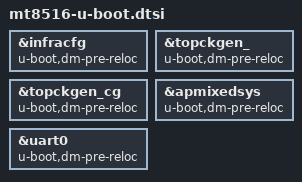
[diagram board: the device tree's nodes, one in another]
// SPDX-License-Identifier: (GPL-2.0 OR MIT)
/*
 * Copyright (C) 2019 BayLibre, SAS
 * Author: Fabien Parent <fparent@baylibre.com>
 */

&infracfg {
	u-boot,dm-pre-reloc;
};

&topckgen_ {
	u-boot,dm-pre-reloc;
};

&topckgen_cg {
	u-boot,dm-pre-reloc;
};

&apmixedsys {
	u-boot,dm-pre-reloc;
};

&uart0 {
	u-boot,dm-pre-reloc;
};
